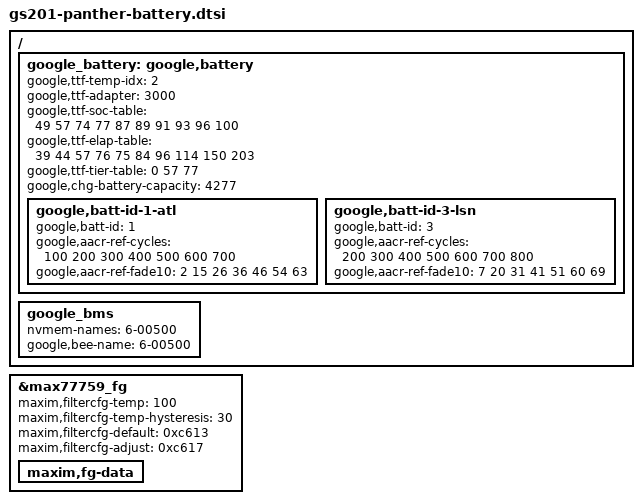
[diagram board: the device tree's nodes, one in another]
// SPDX-License-Identifier: GPL-2.0-only
/*
 * Battery device tree entries specific to panther
 *
 * Copyright 2021 Google,LLC
 *
 */

&google_battery {
	google,chg-battery-capacity = <4277>;
};

&max77759_fg {
	/delete-property/ maxim,force-batt-id;

	maxim,filtercfg-temp = <100>;
	maxim,filtercfg-temp-hysteresis = <30>;
	maxim,filtercfg-default = /bits/ 16 <0xc613>;
	maxim,filtercfg-adjust = /bits/ 16 <0xc617>;

	maxim,fg-data {
		#include "gs201-panther-battery-data.dtsi"
	};
};

/ {
	fragment@battery {
		target-path = "/";
		__overlay__ {
			google_battery: google,battery {
				google,ttf-temp-idx= <2>;
				google,ttf-adapter = <3000>;
				google,ttf-soc-table =  <49 57 74 77 87 89 91 93  96  100>;
				google,ttf-elap-table = <39 44 57 76 75 84 96 114 150 203>;
				google,ttf-tier-table = <0 57 77>;

				google,batt-id-1-atl {
					google,batt-id = <1>;
					google,aacr-ref-cycles = <100 200 300 400 500 600 700>;
					google,aacr-ref-fade10 = <  2  15  26  36  46  54  63>;
				};

				google,batt-id-3-lsn {
					google,batt-id = <3>;
					google,aacr-ref-cycles = <200 300 400 500 600 700 800>;
					google,aacr-ref-fade10 = <  7  20  31  41  51  60  69>;
				};
			};

			google_bms {
				nvmem-names = "6-00500";
				/* pack eeprom is available only with P20+ batteries */
				google,bee-name = "6-00500";
			};
		};
	};
};
